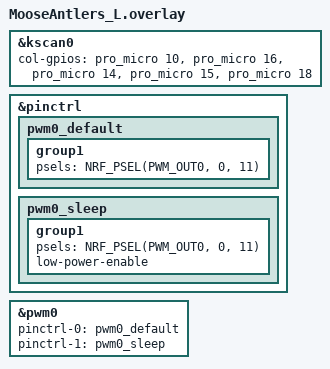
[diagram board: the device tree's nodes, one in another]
#include "MooseAntlers.dtsi" // The shared dtsi file is included in the overlay

// Label of the kscan node in the dtsi
&kscan0 {
    col-gpios
        = <&pro_micro 10 GPIO_ACTIVE_HIGH>
        , <&pro_micro 16 GPIO_ACTIVE_HIGH>
        , <&pro_micro 14 GPIO_ACTIVE_HIGH>
        , <&pro_micro 15 GPIO_ACTIVE_HIGH>
        , <&pro_micro 18 GPIO_ACTIVE_HIGH>
        ;
};

&pinctrl {
    // Other pinctrl definitions for other hardware
    pwm0_default: pwm0_default {
        group1 {
            psels = <NRF_PSEL(PWM_OUT0, 0, 11)>;
        };
    };
    pwm0_sleep: pwm0_sleep {
        group1 {
            psels = <NRF_PSEL(PWM_OUT0, 0, 11)>;
            low-power-enable;
        };
    };
};

&pwm0 {
    status = "okay";
    pinctrl-0 = <&pwm0_default>;
    pinctrl-1 = <&pwm0_sleep>;
    pinctrl-names = "default", "sleep";
};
